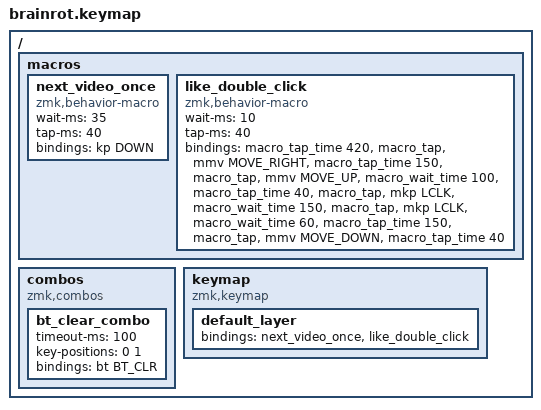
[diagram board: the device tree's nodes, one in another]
#include <behaviors.dtsi>
#include <dt-bindings/zmk/keys.h>
#include <dt-bindings/zmk/bt.h>

/* 150 мс движения дают около 300 px на HONOR Pad X9. */
#define ZMK_POINTING_DEFAULT_MOVE_VAL 4200
#include <dt-bindings/zmk/pointing.h>

/ {
    macros {
        /* 006 / P0.06: одно нажатие стрелки вниз, даже если кнопку удерживать. */
        next_video_once: next_video_once {
            compatible = "zmk,behavior-macro";
            #binding-cells = <0>;
            wait-ms = <35>;
            tap-ms = <40>;
            bindings = <&kp DOWN>;
        };

        /*
         * 008 / P0.08: вправо до края, вверх, двойной клик, вниз.
         * Оба вертикальных движения имеют одинаковые скорость и длительность.
         */
        like_double_click: like_double_click {
            compatible = "zmk,behavior-macro";
            #binding-cells = <0>;
            wait-ms = <10>;
            tap-ms = <40>;

            bindings
                = <&macro_tap_time 420>
                , <&macro_tap &mmv MOVE_RIGHT>
                , <&macro_tap_time 150>
                , <&macro_tap &mmv MOVE_UP>
                , <&macro_wait_time 100>
                , <&macro_tap_time 40>
                , <&macro_tap &mkp LCLK>
                , <&macro_wait_time 150>
                , <&macro_tap &mkp LCLK>
                , <&macro_wait_time 60>
                , <&macro_tap_time 150>
                , <&macro_tap &mmv MOVE_DOWN>
                , <&macro_tap_time 40>
                ;
        };
    };

    combos {
        compatible = "zmk,combos";

        bt_clear_combo {
            timeout-ms = <100>;
            key-positions = <0 1>;
            bindings = <&bt BT_CLR>;
        };
    };

    keymap {
        compatible = "zmk,keymap";

        default_layer {
            bindings = <
                &next_video_once            /* 006 / P0.06 — следующее видео */
                &like_double_click           /* 008 / P0.08 — лайк */
            >;
        };
    };
};
